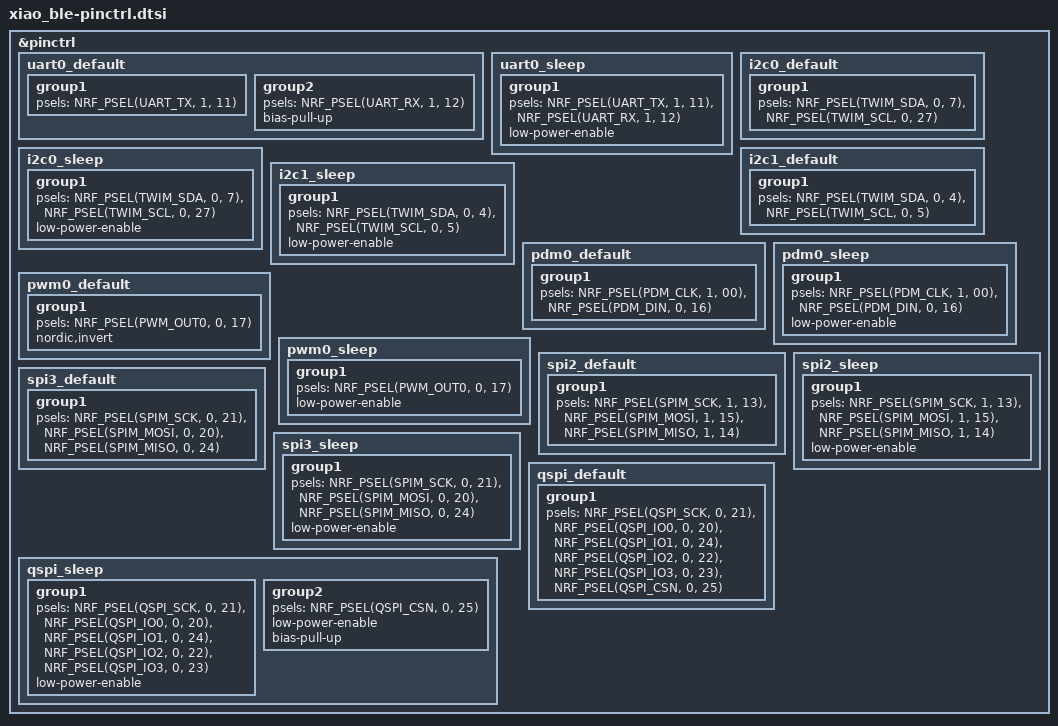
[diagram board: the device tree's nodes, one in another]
/*
 * Copyright (c) 2022 Marcin Niestroj
 * SPDX-License-Identifier: Apache-2.0
 */

&pinctrl {
	uart0_default: uart0_default {
		group1 {
			psels = <NRF_PSEL(UART_TX, 1, 11)>;
		};
		group2 {
			psels = <NRF_PSEL(UART_RX, 1, 12)>;
			bias-pull-up;
		};
	};

	uart0_sleep: uart0_sleep {
		group1 {
			psels = <NRF_PSEL(UART_TX, 1, 11)>,
				<NRF_PSEL(UART_RX, 1, 12)>;
			low-power-enable;
		};
	};

	i2c0_default: i2c0_default {
		group1 {
			psels = <NRF_PSEL(TWIM_SDA, 0, 7)>,
				<NRF_PSEL(TWIM_SCL, 0, 27)>;
		};
	};

	i2c0_sleep: i2c0_sleep {
		group1 {
			psels = <NRF_PSEL(TWIM_SDA, 0, 7)>,
				<NRF_PSEL(TWIM_SCL, 0, 27)>;
			low-power-enable;
		};
	};

	i2c1_default: i2c1_default {
		group1 {
			psels = <NRF_PSEL(TWIM_SDA, 0, 4)>,
				<NRF_PSEL(TWIM_SCL, 0, 5)>;
		};
	};

	i2c1_sleep: i2c1_sleep {
		group1 {
			psels = <NRF_PSEL(TWIM_SDA, 0, 4)>,
				<NRF_PSEL(TWIM_SCL, 0, 5)>;
			low-power-enable;
		};
	};

	pdm0_default: pdm0_default {
		group1 {
			psels = <NRF_PSEL(PDM_CLK, 1, 00)>,
				<NRF_PSEL(PDM_DIN, 0, 16)>;
		};
	};

	pdm0_sleep: pdm0_sleep {
		group1 {
			psels = <NRF_PSEL(PDM_CLK, 1, 00)>,
				<NRF_PSEL(PDM_DIN, 0, 16)>;
				low-power-enable;
		};
	};

	pwm0_default: pwm0_default {
		group1 {
			psels = <NRF_PSEL(PWM_OUT0, 0, 17)>;
			nordic,invert;
		};
	};

	pwm0_sleep: pwm0_sleep {
		group1 {
			psels = <NRF_PSEL(PWM_OUT0, 0, 17)>;
			low-power-enable;
		};
	};

	spi2_default: spi2_default {
		group1 {
			psels = <NRF_PSEL(SPIM_SCK, 1, 13)>,
				<NRF_PSEL(SPIM_MOSI, 1, 15)>,
				<NRF_PSEL(SPIM_MISO, 1, 14)>;
		};
	};

	spi2_sleep: spi2_sleep {
		group1 {
			psels = <NRF_PSEL(SPIM_SCK, 1, 13)>,
				<NRF_PSEL(SPIM_MOSI, 1, 15)>,
				<NRF_PSEL(SPIM_MISO, 1, 14)>;
			low-power-enable;
		};
	};

	spi3_default: spi3_default {
		group1 {
			psels = <NRF_PSEL(SPIM_SCK, 0, 21)>,
				<NRF_PSEL(SPIM_MOSI, 0, 20)>,
				<NRF_PSEL(SPIM_MISO, 0, 24)>;
		};
	};

	spi3_sleep: spi3_sleep {
		group1 {
			psels = <NRF_PSEL(SPIM_SCK, 0, 21)>,
				<NRF_PSEL(SPIM_MOSI, 0, 20)>,
				<NRF_PSEL(SPIM_MISO, 0, 24)>;
			low-power-enable;
		};
	};

	qspi_default: qspi_default {
		group1 {
			psels = <NRF_PSEL(QSPI_SCK, 0, 21)>,
				<NRF_PSEL(QSPI_IO0, 0, 20)>,
				<NRF_PSEL(QSPI_IO1, 0, 24)>,
				<NRF_PSEL(QSPI_IO2, 0, 22)>,
				<NRF_PSEL(QSPI_IO3, 0, 23)>,
				<NRF_PSEL(QSPI_CSN, 0, 25)>;
		};
	};

	qspi_sleep: qspi_sleep {
		group1 {
			psels = <NRF_PSEL(QSPI_SCK, 0, 21)>,
				<NRF_PSEL(QSPI_IO0, 0, 20)>,
				<NRF_PSEL(QSPI_IO1, 0, 24)>,
				<NRF_PSEL(QSPI_IO2, 0, 22)>,
				<NRF_PSEL(QSPI_IO3, 0, 23)>;
			low-power-enable;
		};
		group2 {
			psels = <NRF_PSEL(QSPI_CSN, 0, 25)>;
			low-power-enable;
			bias-pull-up;
		};
	};
};
